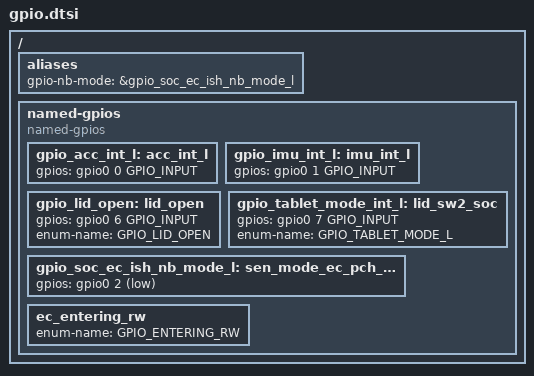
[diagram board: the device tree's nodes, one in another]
/* Copyright 2024 The ChromiumOS Authors
 * Use of this source code is governed by a BSD-style license that can be
 * found in the LICENSE file.
 */
#include <dt-bindings/gpio_defines.h>

/ {

	aliases {
		gpio-nb-mode = &gpio_soc_ec_ish_nb_mode_l;
	};

	named-gpios {
		compatible = "named-gpios";

		gpio_acc_int_l: acc_int_l {
			gpios = <&gpio0 0 GPIO_INPUT>;
		};

		gpio_imu_int_l: imu_int_l {
			gpios = <&gpio0 1 GPIO_INPUT>;
		};

		gpio_lid_open: lid_open {
			gpios = <&gpio0 6 GPIO_INPUT>;
			enum-name = "GPIO_LID_OPEN";
		};

		gpio_tablet_mode_int_l: lid_sw2_soc {
			gpios = <&gpio0 7 GPIO_INPUT>;
			enum-name = "GPIO_TABLET_MODE_L";
		};

		gpio_soc_ec_ish_nb_mode_l: sen_mode_ec_pch_int_odl {
			gpios = <&gpio0 2 (GPIO_ACTIVE_LOW | GPIO_OUTPUT_ACTIVE)>;
		};

		ec_entering_rw {
			enum-name = "GPIO_ENTERING_RW";
		};
	};
};
